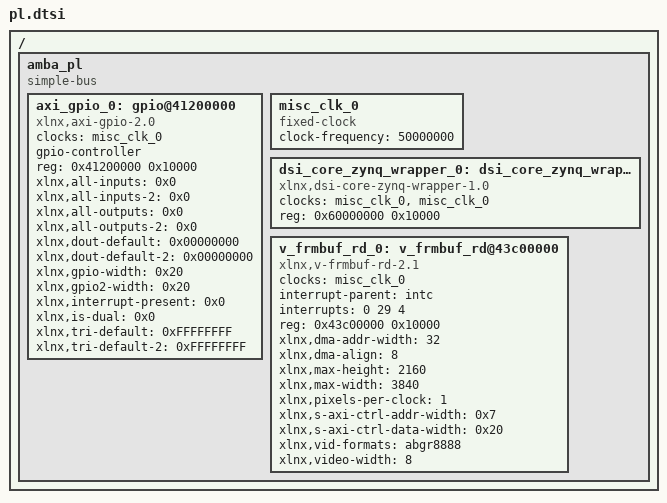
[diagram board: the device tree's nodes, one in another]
/*
 * CAUTION: This file is automatically generated by Xilinx.
 * Version: HSI 2018.3.1
 * Today is: Sun May 12 16:37:27 2019
 */


/ {
	amba_pl: amba_pl {
		#address-cells = <1>;
		#size-cells = <1>;
		compatible = "simple-bus";
		ranges ;
		axi_gpio_0: gpio@41200000 {
			#gpio-cells = <3>;
			clock-names = "s_axi_aclk";
			clocks = <&misc_clk_0>;
			compatible = "xlnx,axi-gpio-2.0", "xlnx,xps-gpio-1.00.a";
			gpio-controller ;
			reg = <0x41200000 0x10000>;
			xlnx,all-inputs = <0x0>;
			xlnx,all-inputs-2 = <0x0>;
			xlnx,all-outputs = <0x0>;
			xlnx,all-outputs-2 = <0x0>;
			xlnx,dout-default = <0x00000000>;
			xlnx,dout-default-2 = <0x00000000>;
			xlnx,gpio-width = <0x20>;
			xlnx,gpio2-width = <0x20>;
			xlnx,interrupt-present = <0x0>;
			xlnx,is-dual = <0x0>;
			xlnx,tri-default = <0xFFFFFFFF>;
			xlnx,tri-default-2 = <0xFFFFFFFF>;
		};
		misc_clk_0: misc_clk_0 {
			#clock-cells = <0>;
			clock-frequency = <50000000>;
			compatible = "fixed-clock";
		};
		dsi_core_zynq_wrapper_0: dsi_core_zynq_wrapper@60000000 {
			/* This is a place holder node for a custom IP, user may need to update the entries */
			clock-names = "s_axil_ACLK", "s_axis_aclk";
			clocks = <&misc_clk_0>, <&misc_clk_0>;
			compatible = "xlnx,dsi-core-zynq-wrapper-1.0";
			reg = <0x60000000 0x10000>;
		};
		v_frmbuf_rd_0: v_frmbuf_rd@43c00000 {
			#dma-cells = <1>;
			clock-names = "ap_clk";
			clocks = <&misc_clk_0>;
			compatible = "xlnx,v-frmbuf-rd-2.1", "xlnx,axi-frmbuf-rd-v2.1";
			interrupt-names = "interrupt";
			interrupt-parent = <&intc>;
			interrupts = <0 29 4>;
			reg = <0x43c00000 0x10000>;
			xlnx,dma-addr-width = <32>;
			xlnx,dma-align = <8>;
			xlnx,max-height = <2160>;
			xlnx,max-width = <3840>;
			xlnx,pixels-per-clock = <1>;
			xlnx,s-axi-ctrl-addr-width = <0x7>;
			xlnx,s-axi-ctrl-data-width = <0x20>;
			xlnx,vid-formats = "abgr8888";
			xlnx,video-width = <8>;
		};
	};
};
